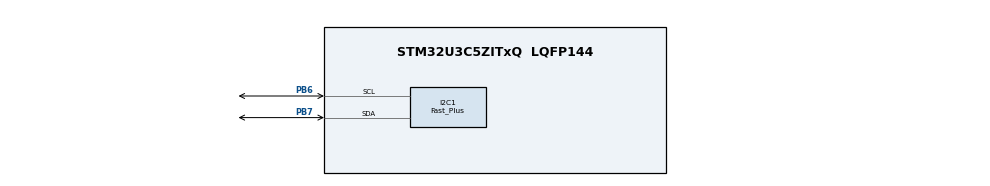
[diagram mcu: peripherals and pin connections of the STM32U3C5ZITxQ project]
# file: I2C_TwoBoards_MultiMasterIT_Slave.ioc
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CORTEX_M33_NS.userName=CORTEX_M33
I2C1.I2C_Fall_Time=2
I2C1.I2C_Rise_Time=26
I2C1.I2C_Speed_Mode=I2C_Fast_Plus
I2C1.OwnAddress=I2C_ADDRESS
I2C1.Timing=0x0070123C
Mcu.Family=STM32U3
Mcu.Name=STM32U3C5ZITxQ
Mcu.Package=LQFP144
Mcu.UserConstants=I2C_ADDRESS,0x30
NVIC.I2C1_ER_IRQn=true\:0\:0\:false\:false\:true\:true\:true\:true
NVIC.I2C1_EV_IRQn=true\:0\:0\:false\:false\:true\:true\:true\:true
NVIC.PriorityGroup=NVIC_PRIORITYGROUP_4
PB6.GPIO_Speed=GPIO_SPEED_FREQ_HIGH
PB6.Mode=I2C
PB6.Signal=I2C1_SCL
PB7.GPIO_Speed=GPIO_SPEED_FREQ_HIGH
PB7.Mode=I2C
PB7.Signal=I2C1_SDA
ProjectManager.HeapSize=0x200
ProjectManager.StackSize=0x400
ProjectManager.TargetToolchain=EWARM V9.20
RCC.ADCFreq_Value=96000000
RCC.AHBFreq_Value=96000000
RCC.APB1Freq_Value=96000000
RCC.APB1TimFreq_Value=96000000
RCC.APB2Freq_Value=96000000
RCC.APB2TimFreq_Value=96000000
RCC.APB3Freq_Value=96000000
RCC.CortexFreq_Value=12000000
RCC.HCLKFreq_Value=96000000
RCC.HSE_VALUE=16000000
RCC.HSI48_VALUE=48000000
RCC.HSI_VALUE=16000000
RCC.LSE_VALUE=32768
RCC.LSIDIV_VALUE=32000
RCC.MSISDIV=RCC_MSI_DIV1
RCC.SYSCLKFreq_VALUE=96000000
RCC.USBFreq_Value=96000000
VP_ICACHE_VS_ICACHE.Mode=DirectMappedCache
VP_PWR_VS_DBSignals.Mode=DisableDeadBatterySignals
VP_PWR_VS_LPOM.Mode=PowerOptimisation
VP_PWR_VS_SECSignals.Mode=Security/Privilege
board=custom

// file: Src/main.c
/* USER CODE BEGIN Header */
/**
  ******************************************************************************
  * @file    I2C/I2C_TwoBoards_MultiMasterIT_Slave/Src/stm32u3xx_it.c
  * @author  MCD Application Team
  * @brief   This sample code shows how to use STM32U3xx I2C HAL API to
  *          manage a Communication between two Masters and one Slave
  *          based on Interrupt procedure.
  ******************************************************************************
  * @attention
  *
  * Copyright (c) 2025 STMicroelectronics.
  * All rights reserved.
  *
  * This software is licensed under terms that can be found in the LICENSE file
  * in the root directory of this software component.
  * If no LICENSE file comes with this software, it is provided AS-IS.
  *
  ******************************************************************************
  */
/* USER CODE END Header */
#include "main.h"

I2C_HandleTypeDef hi2c1;

/* USER CODE BEGIN PV */
/* Buffer used for reception */
uint8_t aRxBuffer[11];
__IO uint32_t nbMst1RxCplt = 0;
__IO uint32_t nbMst2RxCplt = 0;
/* USER CODE END PV */

void SystemClock_Config(void);
static void MX_GPIO_Init(void);
static void MX_I2C1_Init(void);
static void MX_ICACHE_Init(void);

int main(void)
{

  /* MCU Configuration--------------------------------------------------------*/

  /* Reset of all peripherals, Initializes the Flash interface and the Systick. */
  HAL_Init();

  /* Configure the system clock */
  SystemClock_Config();

  /* Initialize all configured peripherals */
  MX_GPIO_Init();
  MX_I2C1_Init();
  MX_ICACHE_Init();
  /* USER CODE BEGIN 2 */
  BSP_LED_Init(LD1);

  /* USER CODE END 2 */

  /* Infinite loop */
  /* USER CODE BEGIN WHILE */
  while (1)
  {
    /*##-2- Put I2C peripheral in reception process ###########################*/
    if(HAL_I2C_Slave_Receive_IT(&hi2c1, (uint8_t *)aRxBuffer, RXBUFFERSIZE) != HAL_OK)
    {
      /* Transfer error in reception process */
      Error_Handler();
    }

    /*##-3- Wait for the end of the transfer ###################################*/
    /*  Before starting a new communication transfer, you need to check the current
    state of the peripheral; if it is busy you need to wait for the end of current
    transfer before starting a new one.
    For simplicity reasons, this example is just waiting till the end of the
    transfer, but application may perform other tasks while transfer operation
    is ongoing. */
    while (HAL_I2C_GetState(&hi2c1) != HAL_I2C_STATE_READY)
    {
    }
    /* USER CODE END WHILE */

  }
}

void SystemClock_Config(void)
{
  RCC_OscInitTypeDef RCC_OscInitStruct = {0};
  RCC_ClkInitTypeDef RCC_ClkInitStruct = {0};

  /** Configure the System Power Supply
  */
  if (HAL_PWREx_ConfigSupply(PWR_SMPS_SUPPLY) != HAL_OK)
  {
    Error_Handler();
  }

  /** Enable Epod Booster
  */
  if (HAL_RCCEx_EpodBoosterClkConfig(RCC_EPODBOOSTER_SOURCE_MSIS, RCC_EPODBOOSTER_DIV1) != HAL_OK)
  {
    Error_Handler();
  }
  if (HAL_PWREx_EnableEpodBooster() != HAL_OK)
  {
    Error_Handler();
  }

  /** Configure the main internal regulator output voltage
  */
  if (HAL_PWREx_ControlVoltageScaling(PWR_REGULATOR_VOLTAGE_SCALE1) != HAL_OK)
  {
    Error_Handler();
  }

  /** Set Flash latency before increasing MSIS
  */
  __HAL_FLASH_SET_LATENCY(FLASH_LATENCY_3);

  /** Initializes the CPU, AHB and APB buses clocks
  */
  RCC_OscInitStruct.OscillatorType = RCC_OSCILLATORTYPE_MSIS;
  RCC_OscInitStruct.MSISState = RCC_MSI_ON;
  RCC_OscInitStruct.MSISSource = RCC_MSI_RC0;
  RCC_OscInitStruct.MSISDiv = RCC_MSI_DIV1;
  if (HAL_RCC_OscConfig(&RCC_OscInitStruct) != HAL_OK)
  {
    Error_Handler();
  }

  /** Initializes the CPU, AHB and APB buses clocks
  */
  RCC_ClkInitStruct.ClockType = RCC_CLOCKTYPE_HCLK|RCC_CLOCKTYPE_SYSCLK
                              |RCC_CLOCKTYPE_PCLK1|RCC_CLOCKTYPE_PCLK2
                              |RCC_CLOCKTYPE_PCLK3;
  RCC_ClkInitStruct.SYSCLKSource = RCC_SYSCLKSOURCE_MSIS;
  RCC_ClkInitStruct.AHBCLKDivider = RCC_SYSCLK_DIV1;
  RCC_ClkInitStruct.APB1CLKDivider = RCC_HCLK_DIV1;
  RCC_ClkInitStruct.APB2CLKDivider = RCC_HCLK_DIV1;
  RCC_ClkInitStruct.APB3CLKDivider = RCC_HCLK_DIV1;

  if (HAL_RCC_ClockConfig(&RCC_ClkInitStruct, FLASH_LATENCY_3) != HAL_OK)
  {
    Error_Handler();
  }
}

static void MX_I2C1_Init(void)
{

  hi2c1.Instance = I2C1;
  hi2c1.Init.Timing = 0x0070123C;
  hi2c1.Init.OwnAddress1 = I2C_ADDRESS;
  hi2c1.Init.AddressingMode = I2C_ADDRESSINGMODE_7BIT;
  hi2c1.Init.DualAddressMode = I2C_DUALADDRESS_DISABLE;
  hi2c1.Init.OwnAddress2 = 0;
  hi2c1.Init.OwnAddress2Masks = I2C_OA2_NOMASK;
  hi2c1.Init.GeneralCallMode = I2C_GENERALCALL_DISABLE;
  hi2c1.Init.NoStretchMode = I2C_NOSTRETCH_DISABLE;
  if (HAL_I2C_Init(&hi2c1) != HAL_OK)
  {
    Error_Handler();
  }

  /** Configure Analogue filter
  */
  if (HAL_I2CEx_ConfigAnalogFilter(&hi2c1, I2C_ANALOGFILTER_ENABLE) != HAL_OK)
  {
    Error_Handler();
  }

  /** Configure Digital filter
  */
  if (HAL_I2CEx_ConfigDigitalFilter(&hi2c1, 0) != HAL_OK)
  {
    Error_Handler();
  }

  /** I2C Fast mode Plus enable
  */
  if (HAL_I2CEx_ConfigFastModePlus(&hi2c1, I2C_FASTMODEPLUS_ENABLE) != HAL_OK)
  {
    Error_Handler();
  }

}

static void MX_ICACHE_Init(void)
{

  /** Enable instruction cache in 1-way (direct mapped cache)
  */
  if (HAL_ICACHE_ConfigAssociativityMode(ICACHE_1WAY) != HAL_OK)
  {
    Error_Handler();
  }
  if (HAL_ICACHE_Enable() != HAL_OK)
  {
    Error_Handler();
  }

}

static void MX_GPIO_Init(void)
{

  /* GPIO Ports Clock Enable */
  __HAL_RCC_GPIOB_CLK_ENABLE();

}

/* USER CODE BEGIN 4 */
/**
  * @brief  Rx Transfer completed callback.
  * @param  hi2c: I2C handle
  * @note   This example shows a simple way to report end of IT Rx transfer, and
  *         you can add your own implementation.
  * @retval None
  */
void HAL_I2C_SlaveRxCpltCallback(I2C_HandleTypeDef *hi2c)
{
  /* Count the number of buffer completion received from Master 2 */
  if (aRxBuffer[7] != 0x31)
  {
    nbMst2RxCplt++;
  }
  /* Count the number of buffer completion received from Master 1 */
  else if(aRxBuffer[7] == 0x31)
  {
    nbMst1RxCplt++;
  }
  /* Turn LD1 on: Transfer in reception process is correct */
  BSP_LED_Toggle(LD1);
}

/**
  * @brief  I2C error callbacks.
  * @param  hi2c: I2C handle
  * @note   This example shows a simple way to report transfer error, and you can
  *         add your own implementation.
  * @retval None
  */
 void HAL_I2C_ErrorCallback(I2C_HandleTypeDef *hi2c)
{
  /** Error_Handler() function is called when error occurs.
    * 1- When Slave don't acknowledge it's address, Master restarts communication.
    * 2- When Master don't acknowledge the last data transferred, Slave don't care in this example.
    */
  if (HAL_I2C_GetError(hi2c) == HAL_I2C_ERROR_BERR)
  {
    /* Workaround deadlock appear due to BUS error detection Errata 64209: START badly generated after misplaced STOP */
    /* Workaround deadlock appear due to BUS error detection Errata I2C-090401 : Robustness issue when receiving an
       illegal void message (no SCL edges between a START and a STOP condition) */
    HAL_I2C_DeInit(hi2c);
    HAL_I2C_Init(hi2c);
  }
  else if (HAL_I2C_GetError(hi2c) != HAL_I2C_ERROR_AF)
  {
    Error_Handler();
  }
}
/* USER CODE END 4 */

void Error_Handler(void)
{
  /* USER CODE BEGIN Error_Handler_Debug */
  /* User can add his own implementation to report the HAL error return state */
  __disable_irq();
  while (1)
  {
    BSP_LED_Toggle(LD1);
    HAL_Delay(1000);
  }
  /* USER CODE END Error_Handler_Debug */
}
#ifdef USE_FULL_ASSERT
/**
  * @brief  Reports the name of the source file and the source line number
  *         where the assert_param error has occurred.
  * @param  file: pointer to the source file name
  * @param  line: assert_param error line source number
  * @retval None
  */
void assert_failed(uint8_t *file, uint32_t line)
{
  /* USER CODE BEGIN 6 */
  /* User can add his own implementation to report the file name and line number,
     ex: printf("Wrong parameters value: file %s on line %d\r\n", file, line) */
  Error_Handler();
  /* USER CODE END 6 */
}
#endif /* USE_FULL_ASSERT */
